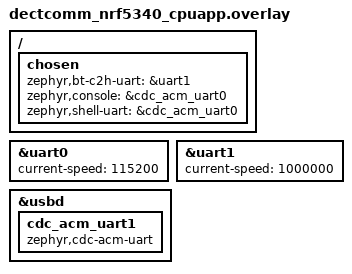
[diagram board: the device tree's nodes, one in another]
/* SPDX-License-Identifier: Apache-2.0 */

/ {
	chosen {
		/* HCI transport to nRF9151 over uart1 */
		zephyr,bt-c2h-uart = &uart1;
		/* 5340 shell/console on USB CDC #0 */
		zephyr,console = &cdc_acm_uart0;
		zephyr,shell-uart = &cdc_acm_uart0;
	};
};

/* uart0: console passthrough to nRF9151 */
&uart0 {
	status = "okay";
	current-speed = <115200>;
};

/* uart1: HCI H4 transport to nRF9151 */
&uart1 {
	status = "okay";
	current-speed = <1000000>;
};

/* USB CDC ACM: add second instance for 9151 console passthrough */
&usbd {
	cdc_acm_uart1: cdc_acm_uart1 {
		compatible = "zephyr,cdc-acm-uart";
	};
};
